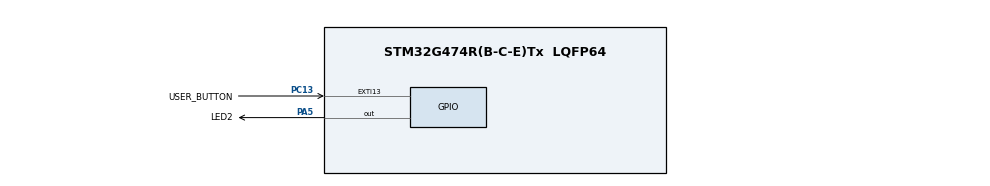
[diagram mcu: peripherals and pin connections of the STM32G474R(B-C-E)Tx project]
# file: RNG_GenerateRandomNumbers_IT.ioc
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Mcu.Family=STM32G4
Mcu.Name=STM32G474R(B-C-E)Tx
Mcu.Package=LQFP64
NVIC.EXTI15_10_IRQn=true\:15\:0\:true\:false\:true\:true\:true\:true
NVIC.PriorityGroup=NVIC_PRIORITYGROUP_4
NVIC.RNG_IRQn=true\:0\:0\:false\:false\:true\:true\:true\:true
PA5.GPIO_Label=LED2
PA5.Signal=GPIO_Output
PC13.GPIO_Label=USER_BUTTON
PC13.GPIO_ModeDefaultEXTI=GPIO_MODE_IT_FALLING
PC13.GPIO_PuPd=GPIO_NOPULL
PC13.Signal=GPXTI13
ProjectManager.HeapSize=0x200
ProjectManager.StackSize=0x400
ProjectManager.TargetToolchain=EWARM V8.32
RCC.ADC12Freq_Value=170000000
RCC.ADC345Freq_Value=170000000
RCC.AHBFreq_Value=170000000
RCC.APB1Freq_Value=170000000
RCC.APB1TimFreq_Value=170000000
RCC.APB2Freq_Value=170000000
RCC.APB2TimFreq_Value=170000000
RCC.CortexFreq_Value=170000000
RCC.EXTERNAL_CLOCK_VALUE=12288000
RCC.HCLKFreq_Value=170000000
RCC.HSE_VALUE=24000000
RCC.HSI48_VALUE=48000000
RCC.HSI_VALUE=16000000
RCC.LSE_VALUE=32768
RCC.PLLM=RCC_PLLM_DIV4
RCC.PLLN=85
RCC.SYSCLKFreq_VALUE=170000000
RCC.SYSCLKSource=RCC_SYSCLKSOURCE_PLLCLK
RCC.USBFreq_Value=170000000
RCC.VCOOutputFreq_Value=340000000
VP_RNG_VS_RNG.Mode=RNG_Activate
VP_SYS_VS_DBSignals.Mode=DisableDeadBatterySignals
board=custom

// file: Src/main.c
/* USER CODE BEGIN Header */
/**
  ******************************************************************************
  * @file    Examples_LL/RNG/RNG_GenerateRandomNumbers_IT/Src/main.c
  * @author  MCD Application Team
  * @brief   This example describes how to use RNG peripheral for generating random
  *          numbers using the STM32G4xx RNG LL API.
  *          Peripheral initialization done using LL unitary services functions.
  ******************************************************************************
  * @attention
  *
  * Copyright (c) 2019 STMicroelectronics.
  * All rights reserved.
  *
  * This software is licensed under terms that can be found in the LICENSE file
  * in the root directory of this software component.
  * If no LICENSE file comes with this software, it is provided AS-IS.
  *
  ******************************************************************************
  */
/* USER CODE END Header */
#include "main.h"

/* USER CODE BEGIN PD */

#if (USE_TIMEOUT == 1)
#define RNG_GENERATION_TIMEOUT   20
#endif /* USE_TIMEOUT */

#define    NB_OF_GENERATED_RANDOM_NUMBERS      8       /* Nb of Random numbers generated after eash User button press */

/* USER CODE END PD */

/* USER CODE BEGIN PV */

#if (USE_TIMEOUT == 1)
uint32_t Timeout = 0; /* Variable used for Timeout management */
#endif /* USE_TIMEOUT */
__IO uint8_t ubButtonPress = 0;
__IO uint8_t ubIndex = 0;
__IO uint8_t ubIsNbGenerated = 0;

/* Array used for storing generated Random 32bit Numbers */
__IO uint32_t aRandom32bit[NB_OF_GENERATED_RANDOM_NUMBERS];

/* USER CODE END PV */

void SystemClock_Config(void);
static void MX_GPIO_Init(void);
static void MX_RNG_Init(void);
/* USER CODE BEGIN PFP */

void     RandomNumbersGenerationIT(void);
void     LED_On(void);
void     LED_Blinking(uint32_t Period);
void     WaitForUserButtonPress(void);

/* USER CODE END PFP */

int main(void)
{

  /* MCU Configuration--------------------------------------------------------*/

  /* Reset of all peripherals, Initializes the Flash interface and the Systick. */

  LL_APB2_GRP1_EnableClock(LL_APB2_GRP1_PERIPH_SYSCFG);
  LL_APB1_GRP1_EnableClock(LL_APB1_GRP1_PERIPH_PWR);

  NVIC_SetPriorityGrouping(NVIC_PRIORITYGROUP_4);

  /* System interrupt init*/

  /** Disable the internal Pull-Up in Dead Battery pins of UCPD peripheral
  */
  LL_PWR_DisableUCPDDeadBattery();

  /* Configure the system clock */
  SystemClock_Config();

  /* Initialize all configured peripherals */
  MX_GPIO_Init();
  MX_RNG_Init();
  /* USER CODE BEGIN 2 */

  /* Wait for User push-button press to trigger random numbers generation */
  WaitForUserButtonPress();

  /* Generate Random Numbers series */
  RandomNumbersGenerationIT();

  /* USER CODE END 2 */

  /* Infinite loop */
  while (1)
  {

  }
}

void SystemClock_Config(void)
{
  LL_FLASH_SetLatency(LL_FLASH_LATENCY_4);
  while(LL_FLASH_GetLatency() != LL_FLASH_LATENCY_4)
  {
  }
  LL_PWR_EnableRange1BoostMode();
  LL_RCC_HSI_Enable();
   /* Wait till HSI is ready */
  while(LL_RCC_HSI_IsReady() != 1)
  {
  }

  LL_RCC_HSI_SetCalibTrimming(64);
  LL_RCC_PLL_ConfigDomain_SYS(LL_RCC_PLLSOURCE_HSI, LL_RCC_PLLM_DIV_4, 85, LL_RCC_PLLR_DIV_2);
  LL_RCC_PLL_ConfigDomain_48M(LL_RCC_PLLSOURCE_HSI, LL_RCC_PLLM_DIV_4, 85, LL_RCC_PLLQ_DIV_2);
  LL_RCC_PLL_EnableDomain_SYS();
  LL_RCC_PLL_EnableDomain_48M();
  LL_RCC_PLL_Enable();
   /* Wait till PLL is ready */
  while(LL_RCC_PLL_IsReady() != 1)
  {
  }

  LL_RCC_SetSysClkSource(LL_RCC_SYS_CLKSOURCE_PLL);
  LL_RCC_SetAHBPrescaler(LL_RCC_SYSCLK_DIV_2);
   /* Wait till System clock is ready */
  while(LL_RCC_GetSysClkSource() != LL_RCC_SYS_CLKSOURCE_STATUS_PLL)
  {
  }

  /* Insure 1µs transition state at intermediate medium speed clock based on DWT */
  CoreDebug->DEMCR |= CoreDebug_DEMCR_TRCENA_Msk;
  DWT->CTRL |= DWT_CTRL_CYCCNTENA_Msk;
  DWT->CYCCNT = 0;
  while(DWT->CYCCNT < 100);
  /* Set AHB prescaler*/
  LL_RCC_SetAHBPrescaler(LL_RCC_SYSCLK_DIV_1);
  LL_RCC_SetAPB1Prescaler(LL_RCC_APB1_DIV_1);
  LL_RCC_SetAPB2Prescaler(LL_RCC_APB2_DIV_1);

  LL_Init1msTick(170000000);

  LL_SetSystemCoreClock(170000000);
}

static void MX_RNG_Init(void)
{

  LL_RCC_SetRNGClockSource(LL_RCC_RNG_CLKSOURCE_PLL);

  /* Peripheral clock enable */
  LL_AHB2_GRP1_EnableClock(LL_AHB2_GRP1_PERIPH_RNG);

  /* RNG interrupt Init */
  NVIC_SetPriority(RNG_IRQn, NVIC_EncodePriority(NVIC_GetPriorityGrouping(),0, 0));
  NVIC_EnableIRQ(RNG_IRQn);

  /* USER CODE BEGIN RNG_Init 1 */

  /* Set system to HSI and disable PLL */
  while (LL_RCC_HSI_IsReady() != 1)
  {

  }
  LL_RCC_HSI_SetCalibTrimming(64);
  /* Configure PLLSAI to enable 48M domain
    - Keep same PLLSAI source (HSE) and PLLM factor (DIV8) used for main PLL
    - Select PLL_N & PLL_Q to have a frequency of 48MHz
        * PLL_P output = (((HSE Freq / PLLM) * PLLSAI_N) / PLLSAI_P)
        *              = (((16000000  /   4 ) *    75    ) /    2     ) */
  LL_RCC_PLL_ConfigDomain_48M(LL_RCC_PLLSOURCE_HSI, LL_RCC_PLLM_DIV_4, 75, LL_RCC_PLLQ_DIV_2);

  LL_RCC_PLL_EnableDomain_48M();
  /* Enable PLL*/
  LL_RCC_PLL_Enable();

  /* Wait for PLL ready flag */
  while (LL_RCC_PLL_IsReady() != 1)
  {
  }

  /* Sysclk activation on the main PLL */
  LL_RCC_SetSysClkSource(LL_RCC_SYS_CLKSOURCE_PLL);

  while (LL_RCC_GetSysClkSource() != LL_RCC_SYS_CLKSOURCE_STATUS_PLL)
  {

  }

  /* Set systick to 1ms */
  SysTick_Config(170000000 / 1000);

  /* Update CMSIS variable (which can be updated also through SystemCoreClockUpdate function) */
  SystemCoreClock = 170000000;

  /* USER CODE END RNG_Init 1 */
  LL_RNG_Enable(RNG);

}

static void MX_GPIO_Init(void)
{
  LL_EXTI_InitTypeDef EXTI_InitStruct = {0};
  LL_GPIO_InitTypeDef GPIO_InitStruct = {0};

  /* GPIO Ports Clock Enable */
  LL_AHB2_GRP1_EnableClock(LL_AHB2_GRP1_PERIPH_GPIOC);
  LL_AHB2_GRP1_EnableClock(LL_AHB2_GRP1_PERIPH_GPIOA);

  /**/
  LL_GPIO_ResetOutputPin(LED2_GPIO_Port, LED2_Pin);

  /**/
  LL_SYSCFG_SetEXTISource(LL_SYSCFG_EXTI_PORTC, LL_SYSCFG_EXTI_LINE13);

  /**/
  EXTI_InitStruct.Line_0_31 = LL_EXTI_LINE_13;
  EXTI_InitStruct.LineCommand = ENABLE;
  EXTI_InitStruct.Mode = LL_EXTI_MODE_IT;
  EXTI_InitStruct.Trigger = LL_EXTI_TRIGGER_FALLING;
  LL_EXTI_Init(&EXTI_InitStruct);

  /**/
  LL_GPIO_SetPinPull(USER_BUTTON_GPIO_Port, USER_BUTTON_Pin, LL_GPIO_PULL_NO);

  /**/
  LL_GPIO_SetPinMode(USER_BUTTON_GPIO_Port, USER_BUTTON_Pin, LL_GPIO_MODE_INPUT);

  /**/
  GPIO_InitStruct.Pin = LED2_Pin;
  GPIO_InitStruct.Mode = LL_GPIO_MODE_OUTPUT;
  GPIO_InitStruct.Speed = LL_GPIO_SPEED_FREQ_LOW;
  GPIO_InitStruct.OutputType = LL_GPIO_OUTPUT_PUSHPULL;
  GPIO_InitStruct.Pull = LL_GPIO_PULL_NO;
  LL_GPIO_Init(LED2_GPIO_Port, &GPIO_InitStruct);

  /* EXTI interrupt init*/
  NVIC_SetPriority(EXTI15_10_IRQn, NVIC_EncodePriority(NVIC_GetPriorityGrouping(),15, 0));
  NVIC_EnableIRQ(EXTI15_10_IRQn);

}

/* USER CODE BEGIN 4 */

/**
  * @brief  This function performs several random numbers generation.
  * @note   Generated random numbers are stored in global variable array, so that
  *         generated values could be observed by user by watching variable content
  *         in specific debugger window
  * @param  None
  * @retval None
  */
void RandomNumbersGenerationIT(void)
{
  /* Initialize random numbers generation */
  LL_RNG_Enable(RNG);

  /* Generate Random 32bit Numbers */
  for(ubIndex = 0; ubIndex < NB_OF_GENERATED_RANDOM_NUMBERS; ubIndex++)
  {
#if (USE_TIMEOUT == 1)
    Timeout = RNG_GENERATION_TIMEOUT;
#endif /* USE_TIMEOUT */

    ubIsNbGenerated = 0;

    /* Enable RNG generation interrupt */
    LL_RNG_EnableIT(RNG);

    /* Wait for Random Number generation completion */
    while (ubIsNbGenerated == 0)
    {
#if (USE_TIMEOUT == 1)
      /* Check Systick counter flag to decrement the time-out value */
      if (LL_SYSTICK_IsActiveCounterFlag())
      {
        if(Timeout-- == 0)
        {
          /* Time-out occurred. Set LED to blinking mode */
          LED_Blinking(LED_BLINK_SLOW);
        }
      }
#endif /* USE_TIMEOUT */
    }
  }

  /* Stop random numbers generation */
  LL_RNG_Disable(RNG);

  /* Values of Generated Random numbers are now available in aRandom32bit array.
     LED2 is turned on */
  LED_On();
}

/**
  * @brief  Turn-on LED2.
  * @param  None
  * @retval None
  */
void LED_On(void)
{
  /* Turn LED2 on */
  LL_GPIO_SetOutputPin(LED2_GPIO_Port, LED2_Pin);
}

/**
  * @brief  Set LED2 to Blinking mode for an infinite loop (toggle period based on value provided as input parameter).
  * @param  Period : Period of time (in ms) between each toggling of LED
  *   This parameter can be user defined values. Pre-defined values used in that example are :
  *     @arg LED_BLINK_FAST : Fast Blinking
  *     @arg LED_BLINK_SLOW : Slow Blinking
  *     @arg LED_BLINK_ERROR : Error specific Blinking
  * @retval None
  */
void LED_Blinking(uint32_t Period)
{
  /* Toggle LED2 in an infinite loop */
  while (1)
  {
    LL_GPIO_TogglePin(LED2_GPIO_Port, LED2_Pin);
    LL_mDelay(Period);
  }
}

/**
  * @brief  Wait for User push-button press to start transfer.
  * @param  None
  * @retval None
  */
  /*  */
void WaitForUserButtonPress(void)
{
  while (ubButtonPress == 0)
  {
    LL_GPIO_TogglePin(LED2_GPIO_Port, LED2_Pin);
    LL_mDelay(LED_BLINK_FAST);
  }

  /* Turn LED2 off */
  LL_GPIO_ResetOutputPin(LED2_GPIO_Port, LED2_Pin);
}

/******************************************************************************/
/*   IRQ HANDLER TREATMENT Functions                                          */
/******************************************************************************/

/**
  * @brief  Function called when RNG IT is triggered with DRDY flag set
  * @param  None
  * @retval None
  */
void RNG_DataReady_Callback(void)
{
  /* Disable RNG IT generation */
  LL_RNG_DisableIT(RNG);

  /* Value of generated random number could be retrieved and stored in dedicated array */
  aRandom32bit[ubIndex] = LL_RNG_ReadRandData32(RNG);

  /* Set Flag indicated random Number generation is completed */
  ubIsNbGenerated = 1;
}

/**
  * @brief  Function called in case of error detected in RNG IT Handler
  * @param  None
  * @retval None
  */
void Error_Callback(void)
{
  /* Disable RNG_IRQn */
  NVIC_DisableIRQ(RNG_IRQn);

  /* Clock or Seed Error detected. Set LED to blinking mode (Error type)*/
  LED_Blinking(LED_BLINK_ERROR);
}

/**
  * @brief  Function to manage User push-button
  * @param  None
  * @retval None
  */
void UserButton_Callback(void)
{
  /* Update User push-button variable : to be checked in waiting loop in main program */
  ubButtonPress = 1;
}

/* USER CODE END 4 */

void Error_Handler(void)
{
}
